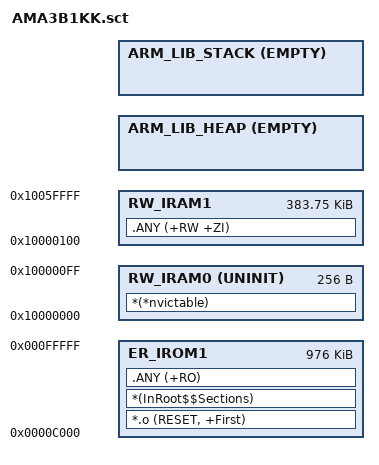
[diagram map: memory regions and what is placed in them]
#! armcc -E

#define MBED_APP_START 0x0000C000
#define MBED_APP_SIZE 0x000F4000
#define MBED_RAM_START 0x10000000
#define MBED_RAM_SIZE   0x60000
#define MBED_RAM0_START MBED_RAM_START
#define MBED_RAM0_SIZE  0x100
#define MBED_RAM1_START (MBED_RAM0_START + MBED_RAM0_SIZE)
#define MBED_RAM1_SIZE  (MBED_RAM_SIZE - (MBED_RAM0_SIZE))
#define Stack_Size MBED_BOOT_STACK_SIZE
#define RAM_FIXED_SIZE   (MBED_BOOT_STACK_SIZE+MBED_RAM0_SIZE)


LR_IROM1 MBED_APP_START MBED_APP_SIZE {
  ER_IROM1 MBED_APP_START MBED_APP_SIZE {
   *.o (RESET, +First)
   *(InRoot$$Sections)
   .ANY (+RO)
  }
  RW_IRAM0 MBED_RAM0_START UNINIT MBED_RAM0_SIZE { ;no init section
        *(*nvictable)
  }
  RW_IRAM1 MBED_RAM1_START MBED_RAM1_SIZE {
   .ANY (+RW +ZI)
  }
  ARM_LIB_HEAP  AlignExpr(+0, 16)  EMPTY  (MBED_RAM_SIZE-RAM_FIXED_SIZE+MBED_RAM_START-AlignExpr(ImageLimit(RW_IRAM1), 16))  {
  }
  ARM_LIB_STACK MBED_RAM1_START+MBED_RAM1_SIZE-8 EMPTY -Stack_Size { ; Stack region growing down
  }
}
